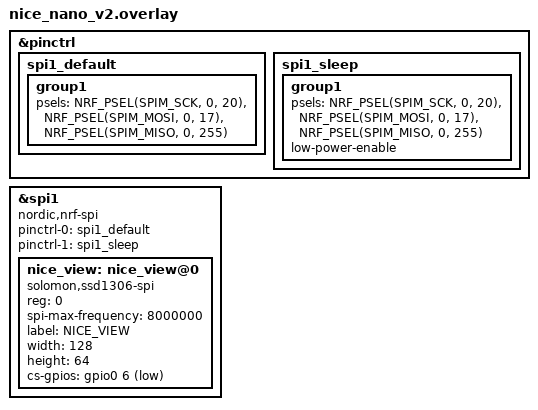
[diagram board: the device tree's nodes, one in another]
//#include <dt-bindings/gpio/gpio.h>

&pinctrl {
    spi1_default: spi1_default {
        group1 {
            psels = <NRF_PSEL(SPIM_SCK, 0, 20)>,
                    <NRF_PSEL(SPIM_MOSI, 0, 17)>,
                    <NRF_PSEL(SPIM_MISO, 0, 255)>;
        };
    };
    spi1_sleep: spi1_sleep {
        group1 {
            psels = <NRF_PSEL(SPIM_SCK, 0, 20)>,
                    <NRF_PSEL(SPIM_MOSI, 0, 17)>,
                    <NRF_PSEL(SPIM_MISO, 0, 255)>;
        low-power-enable;
        };
	};
};

&spi1 {
    compatible = "nordic,nrf-spi";
    pinctrl-0 = <&spi1_default>;
    pinctrl-1= <&spi1_sleep>;
    pinctrl-names = "default", "sleep";

    nice_view: nice_view@0 {
        status = "okay";
        compatible = "solomon,ssd1306-spi";
        reg = <0>;
        spi-max-frequency = <8000000>; // 8 MHz, możesz dostosować
        label = "NICE_VIEW";
        width = <128>;
        height = <64>;
        cs-gpios = <&gpio0 6 GPIO_ACTIVE_LOW>;
    };
};
